# YTM32B1ME1 register map
Vendor: YTMicro; File version: 1.0
CPU: CM33 r0p4, little endian, MPU, FPU, 2 interrupt priority bits
Registers are 32-bit, read-write, reset 0x0 unless marked. A register's access mark holds for its fields unless they carry their own. Offsets are from the block's base; [hi:lo] are bit positions; {n}, {i} and the like mark numbered series.

## TMU — Trigger Multiplexer Module
Base 0x40120000; register names take the prefix TMU_
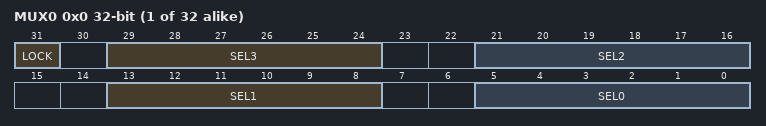
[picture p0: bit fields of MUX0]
{0x0+4i} MUX{i} (i=0..31)
  [31] LOCK — Lock the MUX select for peripheral trigger input
  [8n+5:8n] SEL{n} (n=0..3) — This read/write bit field is used to configure the MUX select for peripheral trigger input.

## IPC — IP Control
Base 0x401F4000; register names take the prefix IPC_
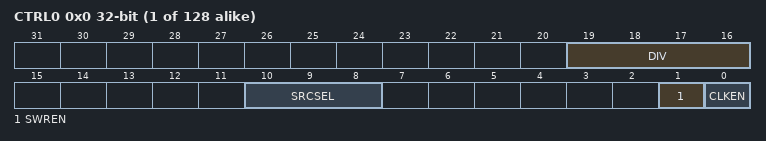
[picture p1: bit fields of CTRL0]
{0x0+4i} CTRL{i} (i=0..127)
  [19:16] DIV — The divider value = register value + 1.
  [10:8] SRCSEL
    0=No clock; 1=FIRC; 2=SIRC; 3=FXOSC; 4=SXOSC; 5=PLL; 6=LPO; 7=FAST_BUS_CLK
  [1] SWREN — Not all modules support, please see \hyperref[ip-clock-control-tab]{Table 13.1 SWR column} for more information.
    0=Software reset is de-asserted; 1=Software reset is asserted
  [0] CLKEN — Not all modules support, please see \hyperref[ip-clock-control-tab]{Table 13.1 Bus Clock Enable column} for more information.
    0=IP clock is disabled; 1=IP clock is enabled

## RCU — Reset Contru Unit of Microcontroller
Base 0x401FC000; register names take the prefix RCU_
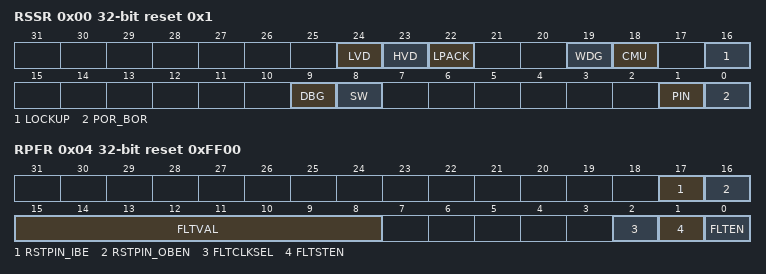
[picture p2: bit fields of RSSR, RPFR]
0x00 RSSR reset 0x1 — This register includes read-only status flags to indicate the source of the most recent reset. Multiple flags will be set if multiple reset events occur at the same time.
  [24] LVD — System reset caused by Low Voltage Detect.
    0=System reset not caused by Low Voltage Detect; 1=System reset caused by Low Voltage Detect
  [23] HVD — System reset caused by Clock Monitor HVD.
    0=System reset not caused by HVD; 1=System reset caused by HVD
  [22] LPACK — System reset caused by Deepsleep/Standby acknowledge timeout. Indicates that after an attempt to enter Deepsleep/Standby mode, a reset has been caused by a failure of one or more peripherals to acknowledge.
    0=System reset not caused by Deepsleep/Standby acknowledge timeout; 1=System reset caused by Deepsleep/Standby acknowledge timeout
  [19] WDG
    0=System reset not caused by WDG; 1=System reset caused by WDG
  [18] CMU — System reset caused by Clock Monitor if CMURE is set.
    0=System reset not caused by CMU; 1=System reset caused by CMU
  [16] LOCKUP — System reset caused by ARM Core Lockup.
    0=System reset not caused by Lockup; 1=System reset caused by Lockup
  [9] DBG — System reset caused by Debug.
    0=System reset not caused by debug; 1=System reset caused by debug
  [8] SW — System reset caused by software to set SYSRESETREQ of ARM Core.
    0=System reset not caused by SW; 1=System reset caused by SW
  [1] PIN — System reset caused by RESET_b pin.
    0=System reset not caused by PIN; 1=System reset caused by PIN
  [0] POR_BOR — System reset caused by POR or BOR.
    0=System reset not caused by POR or BOR; 1=System reset caused by POR or BOR
0x04 RPFR reset 0xFF00 — This register controls the reset pin filter functions.
  [17] RSTPIN_IBE — Enable bit of Reset pin input
    0=reset pin ind is disabled; 1=reset pin ind is enabled
  [16] RSTPIN_OBEN — Enable bit of Reset pin output
    0=Not output low on reset pin when chip reset occurs; 1=Output low on reset pin when chip reset occurs
  [15:8] FLTVAL — FLTVAL control the filter counter value of filter clock cycles. 00000000b - Filter counter value is 0 00000001b - Filter counter value is 1 ... 11111111b - Filter counter value is 255
  [2] FLTCLKSEL — Select LPO_CLK and SIRC_CLK as Reset pin filter clock source
    0=Select LPO_CLK as Reset pin filter clock; 1=Select SIRC_CLK as Reset pin filter clock
  [1] FLTSTEN — Enable bit of Reset pin filter in Deepsleep and Standby mode, this bit should be set if filter need to be used in Deepsleep and Standby mode. This bit has no effect of reset pin filter in RUN mode
    0=Disable reset pin filter in Deepsleep and Standby mode; 1=Enable reset pin filter in Deepsleep and Standby mode if FLTEN is set
  [0] FLTEN — Enable bit of Reset pin filter, this bit should be set if filter need to be used.
    0=Disable reset pin filter; 1=Enable reset pin filter
